# STM32F7x6 register map
File version: 1.6
CPU: CM7 r0p1, little endian, MPU, FPU, 4 interrupt priority bits
Registers are 32-bit, read-write, reset 0x0 unless marked. A register's access mark holds for its fields unless they carry their own. Offsets are from the block's base; [hi:lo] are bit positions; {n}, {i} and the like mark numbered series; 'fields as' and 'values as' point back to an identical list.

## EXTI — External interrupt/event controller
Base 0x40013C00
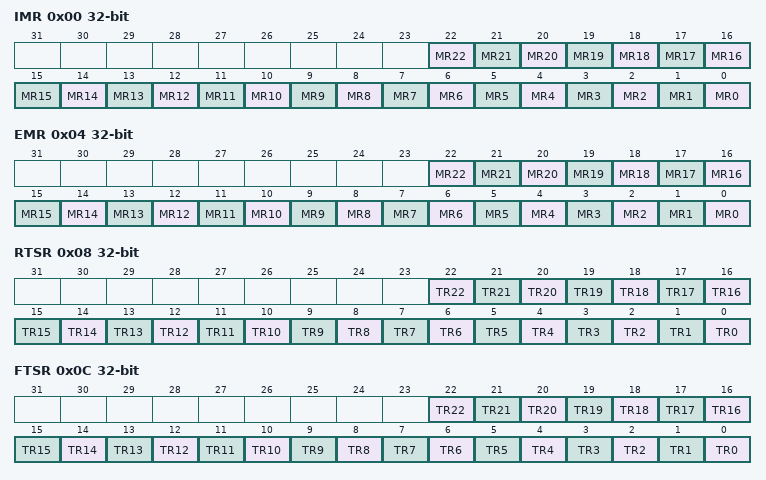
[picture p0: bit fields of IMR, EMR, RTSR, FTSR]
0x00 IMR — Interrupt mask register (EXTI_IMR)
  [all] fields
    0=Masked (Interrupt request line is masked); 1=Unmasked (Interrupt request line is unmasked)
  [n] MR{n} (n=0..22) — Interrupt Mask on line {n}
0x04 EMR — Event mask register (EXTI_EMR)
  [all] fields
    values as the fields of IMR
  [n] MR{n} (n=0..22) — Event Mask on line {n}
0x08 RTSR — Rising Trigger selection register (EXTI_RTSR)
  [all] fields
    0=Disabled (Rising edge trigger is disabled); 1=Enabled (Rising edge trigger is enabled)
  [n] TR{n} (n=0..22) — Rising trigger event configuration of line {n}
0x0C FTSR — Falling Trigger selection register (EXTI_FTSR)
  [all] fields
    0=Disabled (Falling edge trigger is disabled); 1=Enabled (Falling edge trigger is enabled)
  [n] TR{n} (n=0..22) — Falling trigger event configuration of line {n}
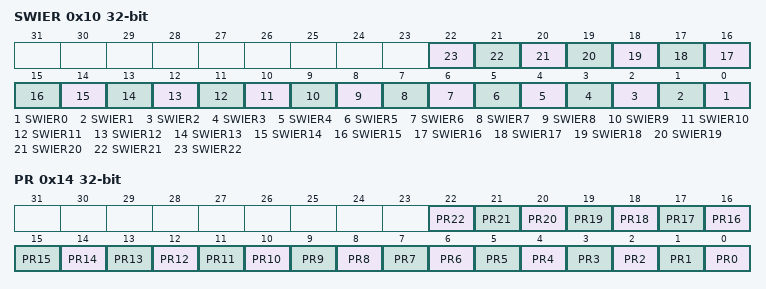
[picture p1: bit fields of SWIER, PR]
0x10 SWIER — Software interrupt event register (EXTI_SWIER)
  [all] fields
    on write: 1=Pend (Generates an interrupt request)
  [n] SWIER{n} (n=0..22) — Software Interrupt on line {n}
0x14 PR — Pending register (EXTI_PR)
  [all] fields
    on read: 0=NotPending (No trigger request occurred); 1=Pending (Selected trigger request occurred) | on write: 1=Clears pending bit
  [n] PR{n} write-1-clears (n=0..22) — Pending bit {n}

## QUADSPI — QuadSPI interface
Base 0xA0001000
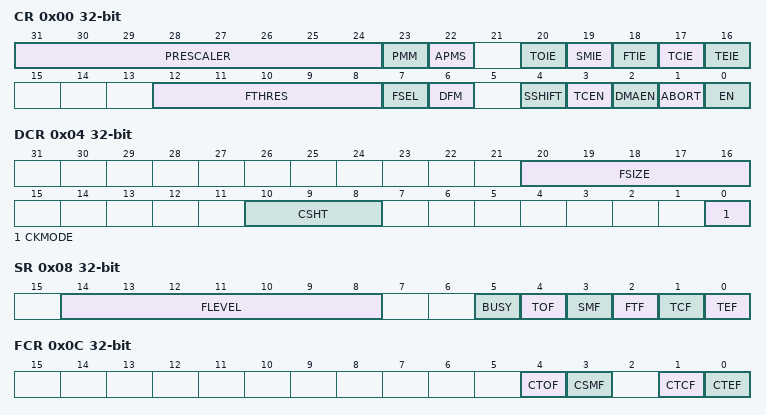
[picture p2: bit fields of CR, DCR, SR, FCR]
0x00 CR — control register
  [31:24] PRESCALER — Clock prescaler
  [23] PMM — Polling match mode
  [22] APMS — Automatic poll mode stop
  [20] TOIE — TimeOut interrupt enable
  [19] SMIE — Status match interrupt enable
  [18] FTIE — FIFO threshold interrupt enable
  [17] TCIE — Transfer complete interrupt enable
  [16] TEIE — Transfer error interrupt enable
  [12:8] FTHRES — IFO threshold level
  [7] FSEL — FLASH memory selection
  [6] DFM — Dual-flash mode
  [4] SSHIFT — Sample shift
  [3] TCEN — Timeout counter enable
  [2] DMAEN — DMA enable
  [1] ABORT — Abort request
  [0] EN — Enable
0x04 DCR — device configuration register
  [20:16] FSIZE — FLASH memory size
  [10:8] CSHT — Chip select high time
  [0] CKMODE — Mode 0 / mode 3
0x08 SR ro — status register
  [14:8] FLEVEL — FIFO level
  [5] BUSY
  [4] TOF — Timeout flag
  [3] SMF — Status match flag
  [2] FTF — FIFO threshold flag
  [1] TCF — Transfer complete flag
  [0] TEF — Transfer error flag
0x0C FCR — flag clear register
  [4] CTOF — Clear timeout flag
  [3] CSMF — Clear status match flag
  [1] CTCF — Clear transfer complete flag
  [0] CTEF — Clear transfer error flag
0x10 DLR — data length register
  [31:0] DL — Data length
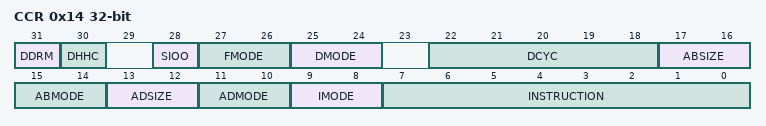
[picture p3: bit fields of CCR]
0x14 CCR — communication configuration register
  [31] DDRM — Double data rate mode
  [30] DHHC — DDR hold half cycle
  [28] SIOO — Send instruction only once mode
  [27:26] FMODE — Functional mode
  [25:24] DMODE — Data mode
  [22:18] DCYC — Number of dummy cycles
  [17:16] ABSIZE — Alternate bytes size
  [15:14] ABMODE — Alternate bytes mode
  [13:12] ADSIZE — Address size
  [11:10] ADMODE — Address mode
  [9:8] IMODE — Instruction mode
  [7:0] INSTRUCTION
0x18 AR — address register
  [31:0] ADDRESS
0x1C ABR
  [31:0] ALTERNATE
0x20 DR — data register
  [31:0] DATA
0x24 PSMKR — polling status mask register
  [31:0] MASK — Status mask
0x28 PSMAR — polling status match register
  [31:0] MATCH — Status match
0x2C PIR — polling interval register
  [15:0] INTERVAL — Polling interval
0x30 LPTR — low-power timeout register
  [15:0] TIMEOUT — Timeout period

## CEC — HDMI-CEC controller
Base 0x40006C00
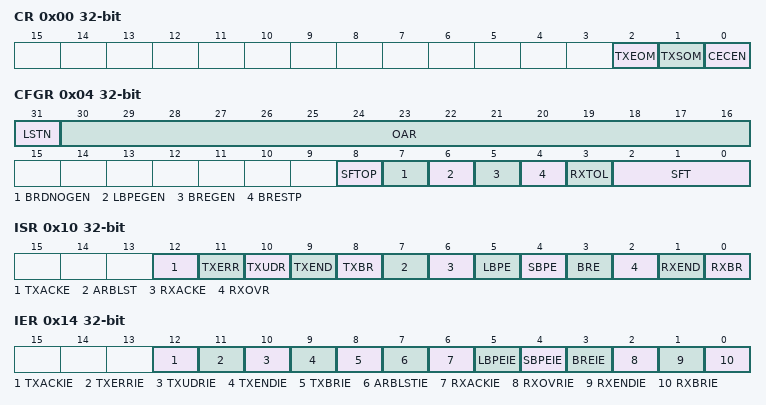
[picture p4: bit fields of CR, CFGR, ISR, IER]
0x00 CR — control register
  [2] TXEOM — Tx End Of Message
  [1] TXSOM — Tx start of message
  [0] CECEN — CEC Enable
0x04 CFGR — configuration register
  [31] LSTN — Listen mode
  [30:16] OAR — Own addresses configuration
  [8] SFTOP — SFT Option Bit
  [7] BRDNOGEN — Avoid Error-Bit Generation in Broadcast
  [6] LBPEGEN — Generate Error-Bit on Long Bit Period Error
  [5] BREGEN — Generate error-bit on bit rising error
  [4] BRESTP — Rx-stop on bit rising error
  [3] RXTOL — Rx-Tolerance
  [2:0] SFT — Signal Free Time
0x08 TXDR wo — Tx data register
  [7:0] TXD — Tx Data register
0x0C RXDR ro — Rx Data Register
  [7:0] RXDR — CEC Rx Data Register
0x10 ISR — Interrupt and Status Register
  [12] TXACKE — Tx-Missing acknowledge error
  [11] TXERR — Tx-Error
  [10] TXUDR — Tx-Buffer Underrun
  [9] TXEND — End of Transmission
  [8] TXBR — Tx-Byte Request
  [7] ARBLST — Arbitration Lost
  [6] RXACKE — Rx-Missing Acknowledge
  [5] LBPE — Rx-Long Bit Period Error
  [4] SBPE — Rx-Short Bit period error
  [3] BRE — Rx-Bit rising error
  [2] RXOVR — Rx-Overrun
  [1] RXEND — End Of Reception
  [0] RXBR — Rx-Byte Received
0x14 IER — interrupt enable register
  [12] TXACKIE — Tx-Missing Acknowledge Error Interrupt Enable
  [11] TXERRIE — Tx-Error Interrupt Enable
  [10] TXUDRIE — Tx-Underrun interrupt enable
  [9] TXENDIE — Tx-End of message interrupt enable
  [8] TXBRIE — Tx-Byte Request Interrupt Enable
  [7] ARBLSTIE — Arbitration Lost Interrupt Enable
  [6] RXACKIE — Rx-Missing Acknowledge Error Interrupt Enable
  [5] LBPEIE — Long Bit Period Error Interrupt Enable
  [4] SBPEIE — Short Bit Period Error Interrupt Enable
  [3] BREIE — Bit Rising Error Interrupt Enable
  [2] RXOVRIE — Rx-Buffer Overrun Interrupt Enable
  [1] RXENDIE — End Of Reception Interrupt Enable
  [0] RXBRIE — Rx-Byte Received Interrupt Enable
